# CC1312PSIP register map
File version: 1.0
CPU: CM4 1.0, other endian, MPU, FPU, 3 interrupt priority bits
Registers are 32-bit, read-write, reset 0x0 unless marked. A register's access mark holds for its fields unless they carry their own. Offsets are from the block's base; [hi:lo] are bit positions; {n}, {i} and the like mark numbered series.

## CPU_SCS (part 2 of 2) — Cortex-M's System Control Space (SCS)
Base 0xE000E000
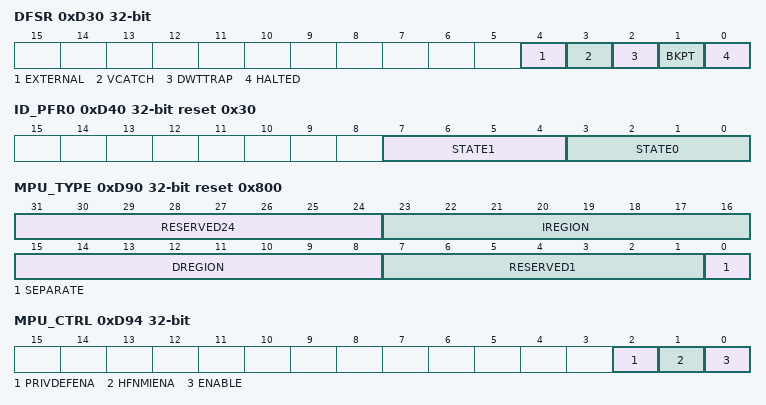
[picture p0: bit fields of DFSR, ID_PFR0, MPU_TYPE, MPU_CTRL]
0xD30 DFSR — Debug Fault Status This register is used to monitor external debug requests, vector catches, data watchpoint match, BKPT instruction execution, halt requests. Multiple flags in the Debug Fault Status Register can be set when multiple fault conditions occur. The register is read/write clear. This means that it can be read normally. Writing a 1 to a bit clears that bit. Note that these bits are not set unless the event is caught. This means that it causes a stop of some sort. If halting debug is enabled, these events stop the processor into debug. If debug is disabled and the debug monitor is enabled, then this becomes a debug monitor handler call, if priority permits. If debug and the monitor are both disabled, some of these events are Hard Faults, and some are ignored.
  [4] EXTERNAL — [4:4] External debug request flag. The processor stops on next instruction boundary. 0x0: External debug request signal not asserted 0x1: External debug request signal asserted
  [3] VCATCH — [3:3] Vector catch flag. When this flag is set, a flag in one of the local fault status registers is also set to indicate the type of fault. 0x0: No vector catch occurred 0x1: Vector catch occurred
  [2] DWTTRAP — [2:2] Data Watchpoint and Trace (DWT) flag. The processor stops at the current instruction or at the next instruction. 0x0: No DWT match 0x1: DWT match
  [1] BKPT — [1:1] BKPT flag. The BKPT flag is set by a BKPT instruction in flash patch code, and also by normal code. Return PC points to breakpoint containing instruction. 0x0: No BKPT instruction execution 0x1: BKPT instruction execution
  [0] HALTED — [0:0] Halt request flag. The processor is halted on the next instruction. 0x0: No halt request 0x1: Halt requested by NVIC, including step
0xD34 MMFAR — Mem Manage Fault Address This register is used to read the address of the location that caused a Memory Manage Fault.
  [31:0] ADDRESS — [31:0] Mem Manage fault address field. This field is the data address of a faulted load or store attempt. When an unaligned access faults, the address is the actual address that faulted. Because an access can be split into multiple parts, each aligned, this address can be any offset in the range of the requested size. Flags CFSR.IACCVIOL, CFSR.DACCVIOL ,CFSR.MUNSTKERR and CFSR.MSTKERR in combination with CFSR.MMARVALIDindicate the cause of the fault.
0xD38 BFAR — Bus Fault Address This register is used to read the address of the location that generated a Bus Fault.
  [31:0] ADDRESS — [31:0] Bus fault address field. This field is the data address of a faulted load or store attempt. When an unaligned access faults, the address is the address requested by the instruction, even if that is not the address that faulted. Flags CFSR.IBUSERR, CFSR.PRECISERR, CFSR.IMPRECISERR, CFSR.UNSTKERR and CFSR.STKERR in combination with CFSR.BFARVALID indicate the cause of the fault.
0xD3C AFSR — Auxiliary Fault Status This register is used to determine additional system fault information to software. Single-cycle high level on an auxiliary faults is latched as one. The bit can only be cleared by writing a one to the corresponding bit. Auxiliary fault inputs to the CPU are tied to 0.
  [31:0] IMPDEF — [31:0] Implementation defined. The bits map directly onto the signal assignment to the auxiliary fault inputs. Tied to 0
0xD40 ID_PFR0 reset 0x30 — Processor Feature 0
  [7:4] STATE1 ro — [7:4] State1 (T-bit == 1) 0x0: N/A 0x1: N/A 0x2: Thumb-2 encoding with the 16-bit basic instructions plus 32-bit Buncond/BL but no other 32-bit basic instructions (Note non-basic 32-bit instructions can be added using the appropriate instruction attribute, but other 32-bit basic instructions cannot.) 0x3: Thumb-2 encoding with all Thumb-2 basic instructions
  [3:0] STATE0 ro — [3:0] State0 (T-bit == 0) 0x0: No ARM encoding 0x1: N/A
0xD44 ID_PFR1 reset 0x200 — Processor Feature 1
  [11:8] MICROCONTROLLER_PROGRAMMERS_MODEL ro — [11:8] Microcontroller programmer's model 0x0: Not supported 0x2: Two-stack support
0xD48 ID_DFR0 reset 0x100000 — Debug Feature 0 This register provides a high level view of the debug system. Further details are provided in the debug infrastructure itself.
  [23:20] MICROCONTROLLER_DEBUG_MODEL ro — [23:20] Microcontroller Debug Model - memory mapped 0x0: Not supported 0x1: Microcontroller debug v1 (ITMv1 and DWTv1)
0xD4C ID_AFR0 — Auxiliary Feature 0 This register provides some freedom for implementation defined features to be registered. Not used in Cortex-M.
0xD50 ID_MMFR0 reset 0x100030 — Memory Model Feature 0 General information on the memory model and memory management support.
0xD54 ID_MMFR1 — Memory Model Feature 1 General information on the memory model and memory management support.
0xD58 ID_MMFR2 reset 0x1000000 — Memory Model Feature 2 General information on the memory model and memory management support.
  [24] WAIT_FOR_INTERRUPT_STALLING ro — [24:24] wait for interrupt stalling 0x0: Not supported 0x1: Wait for interrupt supported
0xD5C ID_MMFR3 — Memory Model Feature 3 General information on the memory model and memory management support.
0xD60 ID_ISAR0 reset 0x1101110 — ISA Feature 0 Information on the instruction set attributes register
0xD64 ID_ISAR1 reset 0x2112000 — ISA Feature 1 Information on the instruction set attributes register
0xD68 ID_ISAR2 reset 0x21232231 — ISA Feature 2 Information on the instruction set attributes register
0xD6C ID_ISAR3 reset 0x1111131 — ISA Feature 3 Information on the instruction set attributes register
0xD70 ID_ISAR4 reset 0x1310132 — ISA Feature 4 Information on the instruction set attributes register
0xD88 CPACR — Coprocessor Access Control This register specifies the access privileges for coprocessors.
0xD90 MPU_TYPE reset 0x800 — MPU Type This register indicates many regions the MPU supports.
  [31:24] RESERVED24 ro — [31:24] Reads 0.
  [23:16] IREGION ro — [23:16] The processor core uses only a unified MPU, this field always reads 0x0.
  [15:8] DREGION ro — [15:8] Number of supported MPU regions field. This field reads 0x08 indicating eight MPU regions.
  [7:1] RESERVED1 ro — [7:1] Reads 0.
  [0] SEPARATE ro — [0:0] The processor core uses only a unified MPU, thus this field is always 0.
0xD94 MPU_CTRL — MPU Control This register is used to enable the MPU, enable the default memory map (background region), and enable the MPU when in Hard Fault, Non-maskable Interrupt (NMI), and FAULTMASK escalated handlers. When the MPU is enabled, at least one region of the memory map must be enabled for the MPU to function unless the PRIVDEFENA bit is set. If the PRIVDEFENA bit is set and no regions are enabled, then only privileged code can operate. When the MPU is disabled, the default address map is used, as if no MPU is present. When the MPU is enabled, only the system partition and vector table loads are always accessible. Other areas are accessible based on regions and whether PRIVDEFENA is enabled. Unless HFNMIENA is set, the MPU is not enabled when the exception priority is -1 or -2. These priorities are only possible when in Hard fault, NMI, or when FAULTMASK is enabled. The HFNMIENA bit enables the MPU when operating with these two priorities.
  [2] PRIVDEFENA — [2:2] This bit enables the default memory map for privileged access, as a background region, when the MPU is enabled. The background region acts as if it was region number 1 before any settable regions. Any region that is set up overlays this default map, and overrides it. If this bit is not set, the default memory map is disabled, and memory not covered by a region faults. This applies to memory type, Execute Never (XN), cache and shareable rules. However, this only applies to privileged mode (fetch and data access). User mode code faults unless a region has been set up for its code and data. When the MPU is disabled, the default map acts on both privileged and user mode code. XN and SO rules always apply to the system partition whether this enable is set or not. If the MPU is disabled, this bit is ignored.
  [1] HFNMIENA — [1:1] This bit enables the MPU when in Hard Fault, NMI, and FAULTMASK escalated handlers. If this bit and ENABLE are set, the MPU is enabled when in these handlers. If this bit is not set, the MPU is disabled when in these handlers, regardless of the value of ENABLE bit. If this bit is set and ENABLE is not set, behavior is unpredictable.
  [0] ENABLE — [0:0] Enable MPU 0: MPU disabled 1: MPU enabled
0xD98 MPU_RNR — MPU Region Number This register is used to select which protection region is accessed. The following write to MPU_RASR or MPU_RBAR configures the characteristics of the protection region that is selected by this register.
  [7:0] REGION — [7:0] Region select field. This field selects the region to operate on when using the MPU_RASR and MPU_RBAR. It must be written first except when the address MPU_RBAR.VALID and MPU_RBAR.REGION fields are written, which overwrites this.
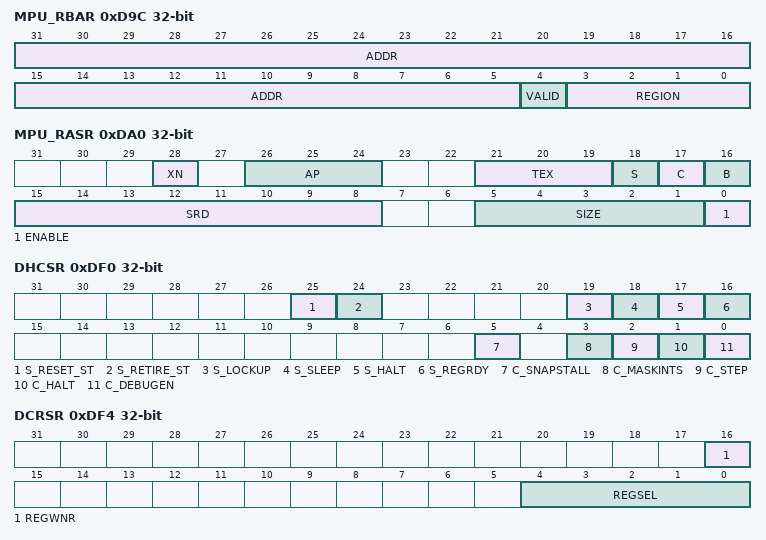
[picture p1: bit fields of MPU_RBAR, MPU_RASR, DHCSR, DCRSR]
0xD9C MPU_RBAR — MPU Region Base Address This register writes the base address of a region. It also contains a REGION field that can be used to override MPU_RNR.REGION, if the VALID bit is set. This register sets the base for the region. It is aligned by the size. So, a 64-KB sized region must be aligned on a multiple of 64KB, for example, 0x00010000 or 0x00020000. The region always reads back as the current MPU region number. VALID always reads back as 0. Writing VALID = 1 and REGION = n changes the region number to n. This is a short-hand way to write the MPU_RNR. This register is unpredictable if accessed other than as a word.
  [31:5] ADDR — [31:5] Region base address field. The position of the LSB depends on the region size, so that the base address is aligned according to an even multiple of size. The power of 2 size specified by the SZENABLE field of the MPU Region Attribute and Size Register defines how many bits of base address are used.
  [4] VALID — [4:4] MPU region number valid: 0: MPU_RNR remains unchanged and is interpreted. 1: MPU_RNR is overwritten by REGION.
  [3:0] REGION — [3:0] MPU region override field
0xDA0 MPU_RASR — MPU Region Attribute and Size This register controls the MPU access permissions. The register is made up of two part registers, each of halfword size. These can be accessed using the halfword size, or they can both be simultaneously accessed using a word operation. The sub-region disable bits are not supported for region sizes of 32 bytes, 64 bytes, and 128 bytes. When these region sizes are used, the subregion disable bits must be programmed as 0.
  [28] XN — [28:28] Instruction access disable: 0: Enable instruction fetches 1: Disable instruction fetches
  [26:24] AP — [26:24] Data access permission: 0x0: Priviliged permissions: No access. User permissions: No access. 0x1: Priviliged permissions: Read-write. User permissions: No access. 0x2: Priviliged permissions: Read-write. User permissions: Read-only. 0x3: Priviliged permissions: Read-write. User permissions: Read-write. 0x4: Reserved 0x5: Priviliged permissions: Read-only. User permissions: No access. 0x6: Priviliged permissions: Read-only. User permissions: Read-only. 0x7: Priviliged permissions: Read-only. User permissions: Read-only.
  [21:19] TEX — [21:19] Type extension
  [18] S — [18:18] Shareable bit: 0: Not shareable 1: Shareable
  [17] C — [17:17] Cacheable bit: 0: Not cacheable 1: Cacheable
  [16] B — [16:16] Bufferable bit: 0: Not bufferable 1: Bufferable
  [15:8] SRD — [15:8] Sub-Region Disable field: Setting a bit in this field disables the corresponding sub-region. Regions are split into eight equal-sized sub-regions. Sub-regions are not supported for region sizes of 128 bytes and less.
  [5:1] SIZE — [5:1] MPU Protection Region Size Field: 0x04: 32B 0x05: 64B 0x06: 128B 0x07: 256B 0x08: 512B 0x09: 1KB 0x0A: 2KB 0x0B: 4KB 0x0C: 8KB 0x0D: 16KB 0x0E: 32KB 0x0F: 64KB 0x10: 128KB 0x11: 256KB 0x12: 512KB 0x13: 1MB 0x14: 2MB 0x15: 4MB 0x16: 8MB 0x17: 16MB 0x18: 32MB 0x19: 64MB 0x1A: 128MB 0x1B: 256MB 0x1C: 512MB 0x1D: 1GB 0x1E: 2GB 0x1F: 4GB
  [0] ENABLE — [0:0] Region enable bit: 0: Disable region 1: Enable region
{0xD9C+8i} MPU_RBAR_A{i} (i=1..3) — MPU Alias {i} Region Base Address Alias for MPU_RBAR
  [31:0] MPU_RBAR_A{i} — [31:0] Alias for MPU_RBAR
{0xDA0+8i} MPU_RASR_A{i} (i=1..3) — MPU Alias {i} Region Attribute and Size Alias for MPU_RASR
  [31:0] MPU_RASR_A{i} — [31:0] Alias for MPU_RASR
0xDF0 DHCSR — Debug Halting Control and Status The purpose of this register is to provide status information about the state of the processor, enable core debug, halt and step the processor. For writes, 0xA05F must be written to higher half-word of this register, otherwise the write operation is ignored and no bits are written into the register. If not enabled for Halting mode, C_DEBUGEN = 1, all other fields are disabled. This register is not reset on a core reset. It is reset by a power-on reset. However, C_HALT always clears on a core reset. To halt on a reset, the following bits must be enabled: DEMCR.VC_CORERESET and C_DEBUGEN. Note that writes to this register in any size other than word are unpredictable. It is acceptable to read in any size, and it can be used to avoid or intentionally change a sticky bit. Behavior of the system when writing to this register while CPU is halted (i.e. C_DEBUGEN = 1 and S_HALT= 1): C_HALT=0, C_STEP=0, C_MASKINTS=0 Exit Debug state and start instruction execution. Exceptions activate according to the exception configuration rules. C_HALT=0, C_STEP=0, C_MASKINTS=1 Exit Debug state and start instruction execution. PendSV, SysTick and external configurable interrupts are disabled, otherwise exceptions activate according to standard configuration rules. C_HALT=0, C_STEP=1, C_MASKINTS=0 Exit Debug state, step an instruction and halt. Exceptions activate according to the exception configuration rules. C_HALT=0, C_STEP=1, C_MASKINTS=1 Exit Debug state, step an instruction and halt. PendSV, SysTick and external configurable interrupts are disabled, otherwise exceptions activate according to standard configuration rules. C_HALT=1, C_STEP=x, C_MASKINTS=x Remain in Debug state
  [25] S_RESET_ST — [25:25] Indicates that the core has been reset, or is now being reset, since the last time this bit was read. This a sticky bit that clears on read. So, reading twice and getting 1 then 0 means it was reset in the past. Reading twice and getting 1 both times means that it is being reset now (held in reset still). When writing to this register, 0 must be written this bit-field, otherwise the write operation is ignored and no bits are written into the register.
  [24] S_RETIRE_ST — [24:24] Indicates that an instruction has completed since last read. This is a sticky bit that clears on read. This determines if the core is stalled on a load/store or fetch. When writing to this register, 0 must be written this bit-field, otherwise the write operation is ignored and no bits are written into the register.
  [19] S_LOCKUP — [19:19] Reads as one if the core is running (not halted) and a lockup condition is present. When writing to this register, 1 must be written this bit-field, otherwise the write operation is ignored and no bits are written into the register.
  [18] S_SLEEP — [18:18] Indicates that the core is sleeping (WFI, WFE, or **SLEEP-ON-EXIT**). Must use C_HALT to gain control or wait for interrupt to wake-up. When writing to this register, 1 must be written this bit-field, otherwise the write operation is ignored and no bits are written into the register.
  [17] S_HALT — [17:17] The core is in debug state when this bit is set. When writing to this register, 1 must be written this bit-field, otherwise the write operation is ignored and no bits are written into the register.
  [16] S_REGRDY — [16:16] Register Read/Write on the Debug Core Register Selector register is available. Last transfer is complete. When writing to this register, 1 must be written this bit-field, otherwise the write operation is ignored and no bits are written into the register.
  [5] C_SNAPSTALL — [5:5] If the core is stalled on a load/store operation the stall ceases and the instruction is forced to complete. This enables Halting debug to gain control of the core. It can only be set if: C_DEBUGEN = 1 and C_HALT = 1. The core reads S_RETIRE_ST as 0. This indicates that no instruction has advanced. This prevents misuse. The bus state is Unpredictable when this is used. S_RETIRE_ST can detect core stalls on load/store operations.
  [3] C_MASKINTS — [3:3] Mask interrupts when stepping or running in halted debug. This masking does not affect NMI, fault exceptions and SVC caused by execution of the instructions. This bit must only be modified when the processor is halted (S_HALT == 1). C_MASKINTS must be set or cleared before halt is released (i.e., the writes to set or clear C_MASKINTS and to set or clear C_HALT must be separate). Modifying C_MASKINTS while the system is running with halting debug support enabled (C_DEBUGEN = 1, S_HALT = 0) may cause unpredictable behavior.
  [2] C_STEP — [2:2] Steps the core in halted debug. When C_DEBUGEN = 0, this bit has no effect. Must only be modified when the processor is halted (S_HALT == 1). Modifying C_STEP while the system is running with halting debug support enabled (C_DEBUGEN = 1, S_HALT = 0) may cause unpredictable behavior.
  [1] C_HALT — [1:1] Halts the core. This bit is set automatically when the core Halts. For example Breakpoint. This bit clears on core reset.
  [0] C_DEBUGEN — [0:0] Enables debug. This can only be written by AHB-AP and not by the core. It is ignored when written by the core, which cannot set or clear it. The core must write a 1 to it when writing C_HALT to halt itself. The values of C_HALT, C_STEP and C_MASKINTS are ignored by hardware when C_DEBUGEN = 0. The read values for C_HALT, C_STEP and C_MASKINTS fields will be unknown to software when C_DEBUGEN = 0.
0xDF4 DCRSR — Deubg Core Register Selector The purpose of this register is to select the processor register to transfer data to or from. This write-only register generates a handshake to the core to transfer data to or from Debug Core Register Data Register and the selected register. Until this core transaction is complete, DHCSR.S_REGRDY is 0. Note that writes to this register in any size but word are Unpredictable. Note that PSR registers are fully accessible this way, whereas some read as 0 when using MRS instructions. Note that all bits can be written, but some combinations cause a fault when execution is resumed.
  [16] REGWNR wo — [16:16] 1: Write 0: Read
  [4:0] REGSEL wo — [4:0] Register select 0x00: R0 0x01: R1 0x02: R2 0x03: R3 0x04: R4 0x05: R5 0x06: R6 0x07: R7 0x08: R8 0x09: R9 0x0A: R10 0x0B: R11 0x0C: R12 0x0D: Current SP 0x0E: LR 0x0F: DebugReturnAddress 0x10: XPSR/flags, execution state information, and exception number 0x11: MSP (Main SP) 0x12: PSP (Process SP) 0x14: CONTROL<<24 | FAULTMASK<<16 | BASEPRI<<8 | PRIMASK
0xDF8 DCRDR — Debug Core Register Data
  [31:0] DCRDR — [31:0] This register holds data for reading and writing registers to and from the processor. This is the data value written to the register selected by DCRSR. When the processor receives a request from DCRSR, this register is read or written by the processor using a normal load-store unit operation. If core register transfers are not being performed, software-based debug monitors can use this register for communication in non-halting debug. This enables flags and bits to acknowledge state and indicate if commands have been accepted to, replied to, or accepted and replied to.
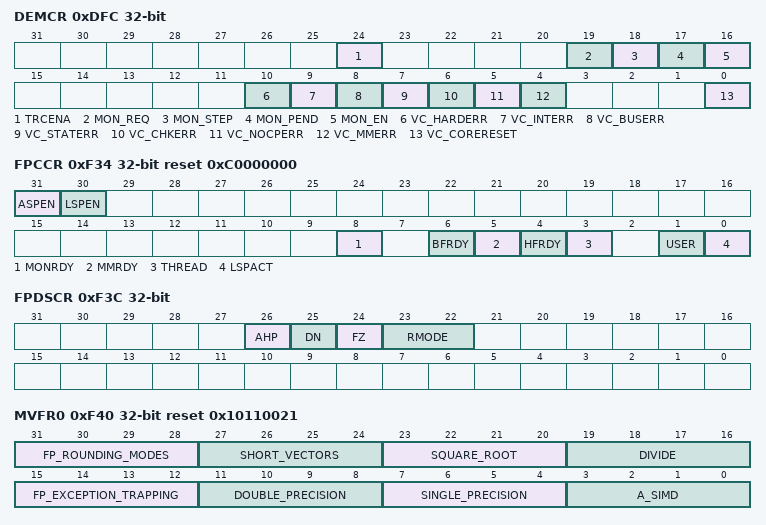
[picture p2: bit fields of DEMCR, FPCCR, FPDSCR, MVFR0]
0xDFC DEMCR — Debug Exception and Monitor Control The purpose of this register is vector catching and debug monitor control. This register manages exception behavior under debug. Vector catching is only available to halting debug. The upper halfword is for monitor controls and the lower halfword is for halting exception support. This register is not reset on a system reset. This register is reset by a power-on reset. The fields MON_EN, MON_PEND, MON_STEP and MON_REQ are always cleared on a core reset. The debug monitor is enabled by software in the reset handler or later, or by the **AHB-AP** port. Vector catching is semi-synchronous. When a matching event is seen, a Halt is requested. Because the processor can only halt on an instruction boundary, it must wait until the next instruction boundary. As a result, it stops on the first instruction of the exception handler. However, two special cases exist when a vector catch has triggered: 1. If a fault is taken during a vector read or stack push error the halt occurs on the corresponding fault handler for the vector error or stack push. 2. If a late arriving interrupt detected during a vector read or stack push error it is not taken. That is, an implementation that supports the late arrival optimization must suppress it in this case.
  [24] TRCENA — [24:24] This bit must be set to 1 to enable use of the trace and debug blocks: DWT, ITM, ETM and TPIU. This enables control of power usage unless tracing is required. The application can enable this, for ITM use, or use by a debugger.
  [19] MON_REQ — [19:19] This enables the monitor to identify how it wakes up. This bit clears on a Core Reset. 0x0: Woken up by debug exception. 0x1: Woken up by MON_PEND
  [18] MON_STEP — [18:18] When MON_EN = 1, this steps the core. When MON_EN = 0, this bit is ignored. This is the equivalent to DHCSR.C_STEP. Interrupts are only stepped according to the priority of the monitor and settings of PRIMASK, FAULTMASK, or BASEPRI.
  [17] MON_PEND — [17:17] Pend the monitor to activate when priority permits. This can wake up the monitor through the AHB-AP port. It is the equivalent to DHCSR.C_HALT for Monitor debug. This register does not reset on a system reset. It is only reset by a power-on reset. Software in the reset handler or later, or by the DAP must enable the debug monitor.
  [16] MON_EN — [16:16] Enable the debug monitor. When enabled, the System handler priority register controls its priority level. If disabled, then all debug events go to Hard fault. DHCSR.C_DEBUGEN overrides this bit. Vector catching is semi-synchronous. When a matching event is seen, a Halt is requested. Because the processor can only halt on an instruction boundary, it must wait until the next instruction boundary. As a result, it stops on the first instruction of the exception handler. However, two special cases exist when a vector catch has triggered: 1. If a fault is taken during vectoring, vector read or stack push error, the halt occurs on the corresponding fault handler, for the vector error or stack push. 2. If a late arriving interrupt comes in during vectoring, it is not taken. That is, an implementation that supports the late arrival optimization must suppress it in this case.
  [10] VC_HARDERR — [10:10] Debug trap on Hard Fault. Ignored when DHCSR.C_DEBUGEN is cleared.
  [9] VC_INTERR — [9:9] Debug trap on a fault occurring during an exception entry or return sequence. Ignored when DHCSR.C_DEBUGEN is cleared.
  [8] VC_BUSERR — [8:8] Debug Trap on normal Bus error. Ignored when DHCSR.C_DEBUGEN is cleared.
  [7] VC_STATERR — [7:7] Debug trap on Usage Fault state errors. Ignored when DHCSR.C_DEBUGEN is cleared.
  [6] VC_CHKERR — [6:6] Debug trap on Usage Fault enabled checking errors. Ignored when DHCSR.C_DEBUGEN is cleared.
  [5] VC_NOCPERR — [5:5] Debug trap on a UsageFault access to a Coprocessor. Ignored when DHCSR.C_DEBUGEN is cleared.
  [4] VC_MMERR — [4:4] Debug trap on Memory Management faults. Ignored when DHCSR.C_DEBUGEN is cleared.
  [0] VC_CORERESET — [0:0] Reset Vector Catch. Halt running system if Core reset occurs. Ignored when DHCSR.C_DEBUGEN is cleared.
0xF00 STIR — Software Trigger Interrupt
  [8:0] INTID wo — [8:0] Interrupt ID field. Writing a value to this bit-field is the same as manually pending an interrupt by setting the corresponding interrupt bit in an Interrupt Set Pending Register in NVIC_ISPR0 or NVIC_ISPR1.
0xF34 FPCCR reset 0xC0000000 — Floating Point Context Control This register holds control data for the floating-point unit. Accessible only by privileged software.
  [31] ASPEN — [31:31] Automatic State Preservation enable. When this bit is set is will cause bit [2] of the Special CONTROL register to be set (FPCA) on execution of a floating point instruction which results in the floating point state automatically being preserved on exception entry.
  [30] LSPEN — [30:30] Lazy State Preservation enable. Lazy state preservation is when the processor performs a context save, space on the stack is reserved for the floating point state but it is not stacked until the new context performs a floating point operation. 0: Disable automatic lazy state preservation for floating-point context. 1: Enable automatic lazy state preservation for floating-point context.
  [8] MONRDY — [8:8] Indicates whether the the software executing when the processor allocated the FP stack frame was able to set the DebugMonitor exception to pending. 0: DebugMonitor is disabled or priority did not permit setting DEMCR.MON_PEND when the floating-point stack frame was allocated. 1: DebugMonitor is enabled and priority permits setting DEMCR.MON_PEND when the floating-point stack frame was allocated.
  [6] BFRDY — [6:6] Indicates whether the software executing when the processor allocated the FP stack frame was able to set the BusFault exception to pending. 0: BusFault is disabled or priority did not permit setting the BusFault handler to the pending state when the floating-point stack frame was allocated. 1: BusFault is enabled and priority permitted setting the BusFault handler to the pending state when the floating-point stack frame was allocated.
  [5] MMRDY — [5:5] Indicates whether the software executing when the processor allocated the FP stack frame was able to set the MemManage exception to pending. 0: MemManage is disabled or priority did not permit setting the MemManage handler to the pending state when the floating-point stack frame was allocated. 1: MemManage is enabled and priority permitted setting the MemManage handler to the pending state when the floating-point stack frame was allocated.
  [4] HFRDY — [4:4] Indicates whether the software executing when the processor allocated the FP stack frame was able to set the HardFault exception to pending. 0: Priority did not permit setting the HardFault handler to the pending state when the floating-point stack frame was allocated. 1: Priority permitted setting the HardFault handler to the pending state when the floating-point stack frame was allocated.
  [3] THREAD — [3:3] Indicates the processor mode was Thread when it allocated the FP stack frame. 0: Mode was not Thread Mode when the floating-point stack frame was allocated. 1: Mode was Thread Mode when the floating-point stack frame was allocated.
  [1] USER — [1:1] Indicates the privilege level of the software executing was User (Unpriviledged) when the processor allocated the FP stack frame: 0: Privilege level was not user when the floating-point stack frame was allocated. 1: Privilege level was user when the floating-point stack frame was allocated.
  [0] LSPACT — [0:0] Indicates whether Lazy preservation of the FP state is active: 0: Lazy state preservation is not active. 1: Lazy state preservation is active. floating-point stack frame has been allocated but saving state to it has been deferred.
0xF38 FPCAR — Floating-Point Context Address This register holds the location of the unpopulated floating-point register space allocated on an exception stack frame.
  [31:2] ADDRESS — [31:2] Holds the (double-word-aligned) location of the unpopulated floating-point register space allocated on an exception stack frame.
0xF3C FPDSCR — Floating Point Default Status Control This register holds the default values for the floating-point status control data that the processor assigns to the FPSCR when it creates a new floating-point context. Accessible only by privileged software.
  [26] AHP — [26:26] Default value for Alternative Half Precision bit. (If this bit is set to 1 then Alternative half-precision format is selected).
  [25] DN — [25:25] Default value for Default NaN mode bit. (If this bit is set to 1 then any operation involving one or more NaNs returns the Default NaN).
  [24] FZ — [24:24] Default value for Flush-to-Zero mode bit. (If this bit is set to 1 then Flush-to-zero mode is enabled).
  [23:22] RMODE — [23:22] Default value for Rounding Mode control field. (The encoding for this field is: 0b00 Round to Nearest (RN) mode 0b01 Round towards Plus Infinity (RP) mode 0b10 Round towards Minus Infinity (RM) mode 0b11 Round towards Zero (RZ) mode. The specified rounding mode is used by almost all floating-point instructions).
0xF40 MVFR0 reset 0x10110021 — Media and FP Feature 0 Describes the features provided by the Floating-point extension.
  [31:28] FP_ROUNDING_MODES ro — [31:28] Indicates the rounding modes supported by the FP floating-point hardware. The value of this field is: 0b0001 - all rounding modes supported.
  [27:24] SHORT_VECTORS ro — [27:24] Indicates the hardware support for FP short vectors. The value of this field is: 0b0000 - not supported.
  [23:20] SQUARE_ROOT ro — [23:20] Indicates the hardware support for FP square root operations. The value of this field is: 0b0001 - supported.
  [19:16] DIVIDE ro — [19:16] Indicates the hardware support for FP divide operations. The value of this field is: 0b0001 - supported.
  [15:12] FP_EXCEPTION_TRAPPING ro — [15:12] Indicates whether the FP hardware implementation supports exception trapping. The value of this field is: 0b0000 - not supported.
  [11:8] DOUBLE_PRECISION ro — [11:8] Indicates the hardware support for FP double-precision operations. The value of this field is: 0b0000 - not supported.
  [7:4] SINGLE_PRECISION ro — [7:4] Indicates the hardware support for FP single-precision operations. The value of this field is: 0b0010 - supported.
  [3:0] A_SIMD ro — [3:0] Indicates the size of the FP register bank. The value of this field is: 0b0001 - supported, 16 x 64-bit registers.
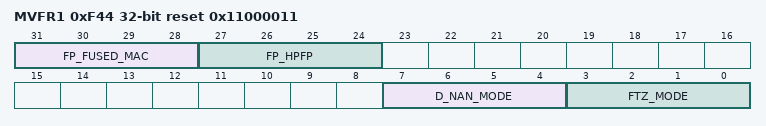
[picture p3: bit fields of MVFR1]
0xF44 MVFR1 reset 0x11000011 — Media and FP Feature 1 Describes the features provided by the Floating-point extension.
  [31:28] FP_FUSED_MAC ro — [31:28] Indicates whether the FP supports fused multiply accumulate operations. The value of this field is: 0b0001 - supported.
  [27:24] FP_HPFP ro — [27:24] Indicates whether the FP supports half-precision floating-point conversion operations. The value of this field is: 0b0001 - supported.
  [7:4] D_NAN_MODE ro — [7:4] Indicates whether the FP hardware implementation supports only the Default NaN mode. The value of this field is: 0b0001 - hardware supports propagation of NaN values.
  [3:0] FTZ_MODE ro — [3:0] Indicates whether the FP hardware implementation supports only the Flush-to-Zero mode of operation. The value of this field is: 0b0001 - hardware supports full denormalized number arithmetic.
